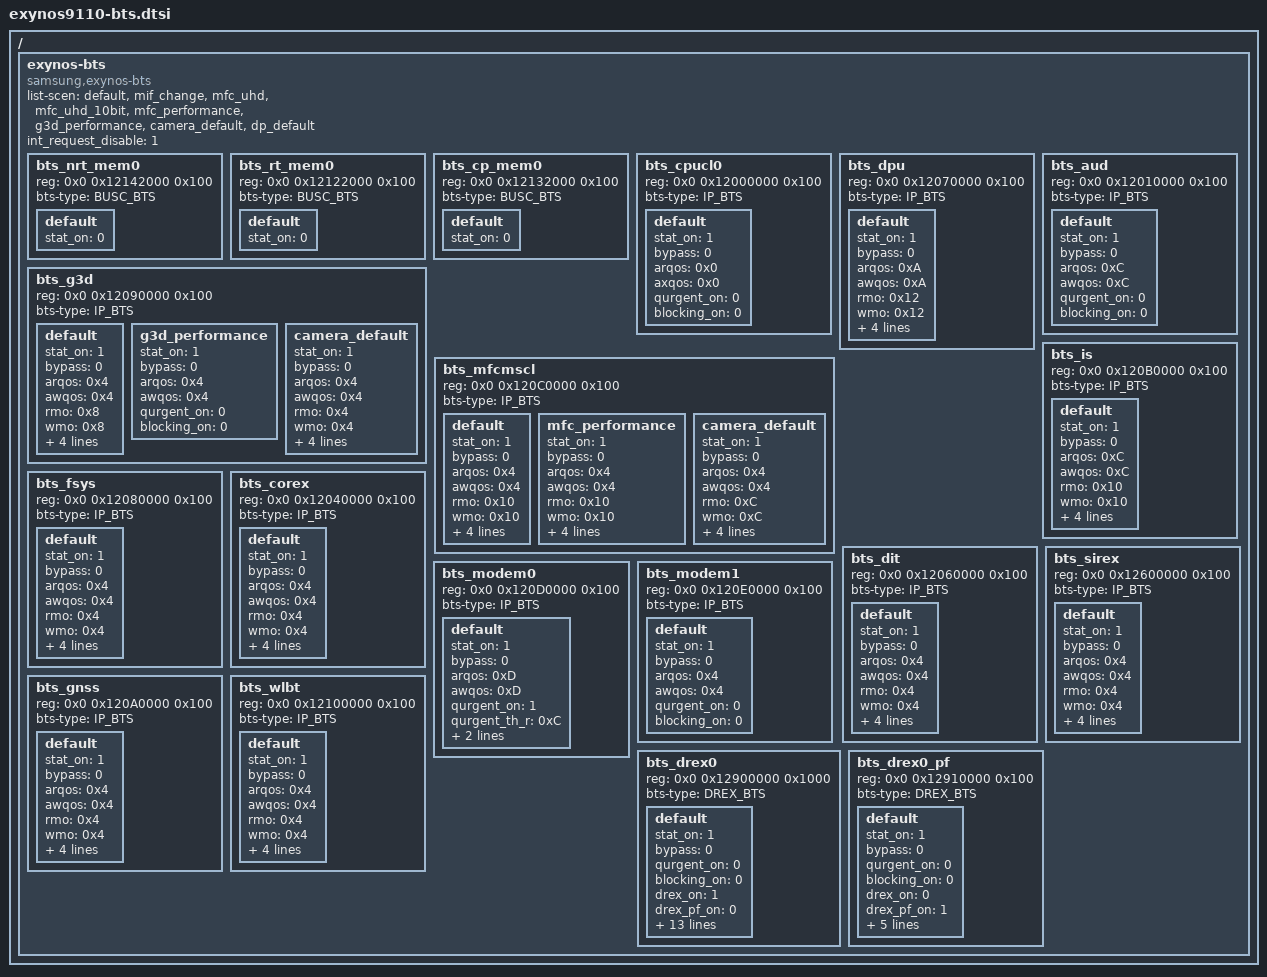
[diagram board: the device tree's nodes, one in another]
/*
 * SAMSUNG EXYNOS SoC BTS device tree source
 *
 * Copyright (c) 2018 Samsung Electronics Co., Ltd.
 *		http://www.samsung.com
 *
 * SAMSUNG EXYNOS SoC BTS device nodes are listed in this file.
 * EXYNOS based board files should include this file.
 *
 * This program is free software; you can redistribute it and/or modify
 * it under the terms of the GNU General Public License version 2 as
 * published by the Free Software Foundation.
 *
 */

#include <dt-bindings/soc/samsung/exynos-bts.h>

/ {
	exynos-bts {
		compatible = "samsung,exynos-bts";
		#address-cells = <2>;
		#size-cells = <1>;
		ranges;

		list-scen = "default",
			    "mif_change",
			    "mfc_uhd",
			    "mfc_uhd_10bit",
			    "mfc_performance",
			    "g3d_performance",
			    "camera_default",
			    "dp_default";

		int_request_disable = <1>;

		bts_nrt_mem0 {
			reg = <0x0 0x12142000 0x100>;
			status = "okay";
			bts-type = <BUSC_BTS>;
			default {
				stat_on = <0>;
			};
		};
		bts_rt_mem0 {
			reg = <0x0 0x12122000 0x100>;
			status = "okay";
			bts-type = <BUSC_BTS>;
			default {
				stat_on = <0>;
			};
		};
		bts_cp_mem0 {
			reg = <0x0 0x12132000 0x100>;
			status = "okay";
			bts-type = <BUSC_BTS>;
			default {
				stat_on = <0>;
			};
		};
		bts_cpucl0 {
			reg = <0x0 0x12000000 0x100>;
			status = "okay";
			bts-type = <IP_BTS>;
			default {
				stat_on = <1>;
				bypass = <0>;
				arqos = <0x0>;
				axqos = <0x0>;
				qurgent_on = <0>;
				blocking_on = <0>;
			};
		};
		bts_dpu {
			reg = <0x0 0x12070000 0x100>;
			status = "okay";
			bts-type = <IP_BTS>;
			default {
				stat_on = <1>;
				bypass = <0>;
				arqos = <0xA>;
				awqos = <0xA>;
				rmo = <0x12>;
				wmo = <0x12>;
				qurgent_on = <1>;
				qurgent_th_r = <0x20>;
				qurgent_th_w = <0x20>;
				blocking_on = <0>;
			};
		};
		bts_aud {
			reg = <0x0 0x12010000 0x100>;
			status = "okay";
			bts-type = <IP_BTS>;
			default {
				stat_on = <1>;
				bypass = <0>;
				arqos = <0xC>;
				awqos = <0xC>;
				qurgent_on = <0>;
				blocking_on = <0>;
			};
		};
		bts_g3d {
			reg = <0x0 0x12090000 0x100>;
			status = "okay";
			bts-type = <IP_BTS>;
			default {
				stat_on = <1>;
				bypass = <0>;
				arqos = <0x4>;
				awqos = <0x4>;
				rmo = <0x8>;
				wmo = <0x8>;
				qurgent_on = <0>;
				blocking_on = <1>;
				qmax0_limit_r = <0x1>;
				qmax0_limit_w = <0x1>;
			};
			g3d_performance {
				stat_on = <1>;
				bypass = <0>;
				arqos = <0x4>;
				awqos = <0x4>;
				qurgent_on = <0>;
				blocking_on = <0>;
			};
			camera_default {
				stat_on = <1>;
				bypass = <0>;
				arqos = <0x4>;
				awqos = <0x4>;
				rmo = <0x4>;
				wmo = <0x4>;
				qurgent_on = <0>;
				blocking_on = <1>;
				qmax0_limit_r = <0x1>;
				qmax0_limit_w = <0x1>;
			};

		};
		bts_mfcmscl {
			reg = <0x0 0x120C0000 0x100>;
			status = "okay";
			bts-type = <IP_BTS>;
			default {
				stat_on = <1>;
				bypass = <0>;
				arqos = <0x4>;
				awqos = <0x4>;
				rmo = <0x10>;
				wmo = <0x10>;
				qurgent_on = <0>;
				blocking_on = <1>;
				qmax0_limit_r = <0x1>;
				qmax0_limit_w = <0x1>;
			};
			mfc_performance {
				stat_on = <1>;
				bypass = <0>;
				arqos = <0x4>;
				awqos = <0x4>;
				rmo = <0x10>;
				wmo = <0x10>;
				qurgent_on = <0>;
				blocking_on = <1>;
				qmax0_limit_r = <0x1>;
				qmax0_limit_w = <0x1>;
			};
			camera_default {
				stat_on = <1>;
				bypass = <0>;
				arqos = <0x4>;
				awqos = <0x4>;
				rmo = <0xC>;
				wmo = <0xC>;
				qurgent_on = <0>;
				blocking_on = <1>;
				qmax0_limit_r = <0x1>;
				qmax0_limit_w = <0x1>;
			};
		};
		bts_is {
			reg = <0x0 0x120B0000 0x100>;
			status = "okay";
			bts-type = <IP_BTS>;
			default {
				stat_on = <1>;
				bypass = <0>;
				arqos = <0xC>;
				awqos = <0xC>;
				rmo = <0x10>;
				wmo = <0x10>;
				qurgent_on = <1>;
				qurgent_th_r = <0x10>;
				qurgent_th_w = <0x10>;
				blocking_on = <0>;
			};
		};
		bts_fsys {
			reg = <0x0 0x12080000 0x100>;
			status = "okay";
			bts-type = <IP_BTS>;
			default {
				stat_on = <1>;
				bypass = <0>;
				arqos = <0x4>;
				awqos = <0x4>;
				rmo = <0x4>;
				wmo = <0x4>;
				qurgent_on = <0>;
				blocking_on = <1>;
				qmax0_limit_r = <0x1>;
				qmax0_limit_w = <0x1>;
			};
		};
		bts_corex {
			reg = <0x0 0x12040000 0x100>;
			status = "okay";
			bts-type = <IP_BTS>;
			default {
				stat_on = <1>;
				bypass = <0>;
				arqos = <0x4>;
				awqos = <0x4>;
				rmo = <0x4>;
				wmo = <0x4>;
				qurgent_on = <0>;
				blocking_on = <1>;
				qmax0_limit_r = <0x1>;
				qmax0_limit_w = <0x1>;
			};
		};
		bts_dit {
			reg = <0x0 0x12060000 0x100>;
			status = "okay";
			bts-type = <IP_BTS>;
			default {
				stat_on = <1>;
				bypass = <0>;
				arqos = <0x4>;
				awqos = <0x4>;
				rmo = <0x4>;
				wmo = <0x4>;
				qurgent_on = <0>;
				blocking_on = <1>;
				qmax0_limit_r = <0x1>;
				qmax0_limit_w = <0x1>;
			};
		};
		bts_sirex {
			reg = <0x0 0x12600000 0x100>;
			status = "okay";
			bts-type = <IP_BTS>;
			default {
				stat_on = <1>;
				bypass = <0>;
				arqos = <0x4>;
				awqos = <0x4>;
				rmo = <0x4>;
				wmo = <0x4>;
				qurgent_on = <0>;
				blocking_on = <1>;
				qmax0_limit_r = <0x1>;
				qmax0_limit_w = <0x1>;
			};
		};
		bts_modem0 {
			reg = <0x0 0x120D0000 0x100>;
			status = "okay";
			bts-type = <IP_BTS>;
			default {
				stat_on = <1>;
				bypass = <0>;
				arqos = <0xD>;
				awqos = <0xD>;
				qurgent_on = <1>;
				qurgent_th_r = <0xC>;
				qurgent_th_w = <0xC>;
				blocking_on = <0>;
			};
		};
		bts_modem1 {
			reg = <0x0 0x120E0000 0x100>;
			status = "okay";
			bts-type = <IP_BTS>;
			default {
				stat_on = <1>;
				bypass = <0>;
				arqos = <0x4>;
				awqos = <0x4>;
				qurgent_on = <0>;
				blocking_on = <0>;
			};
		};
		bts_gnss {
			reg = <0x0 0x120A0000 0x100>;
			status = "okay";
			bts-type = <IP_BTS>;
			default {
				stat_on = <1>;
				bypass = <0>;
				arqos = <0x4>;
				awqos = <0x4>;
				rmo = <0x4>;
				wmo = <0x4>;
				qurgent_on = <0>;
				blocking_on = <1>;
				qmax0_limit_r = <0x1>;
				qmax0_limit_w = <0x1>;
			};
		};
		bts_wlbt {
			reg = <0x0 0x12100000 0x100>;
			status = "okay";
			bts-type = <IP_BTS>;
			default {
				stat_on = <1>;
				bypass = <0>;
				arqos = <0x4>;
				awqos = <0x4>;
				rmo = <0x4>;
				wmo = <0x4>;
				qurgent_on = <0>;
				blocking_on = <1>;
				qmax0_limit_r = <0x1>;
				qmax0_limit_w = <0x1>;
			};
		};

		bts_drex0 {
			reg = <0x0 0x12900000 0x1000>;
			status = "okay";
			bts-type = <DREX_BTS>;
			default {
				stat_on = <1>;
				bypass = <0>;
				qurgent_on = <0>;
				blocking_on = <0>;
				drex_on = <1>;
				drex_pf_on = <0>;
				write_flush_config_0 = <0x50100C02>;
				write_flush_config_1 = <0x1008100A>;
				drex_timeout = <0x000A0180>,
					     <0x000A0100>,
					     <0x000A0100>,
					     <0x000A0100>,
					     <0x000A0100>,
					     <0x000A0100>,
					     <0x000A0100>,
					     <0x000A0100>,
					     <0x000A0080>,
					     <0x000A0060>,
					     <0x000A0040>,
					     <0x000A0020>,
					     <0x000A0010>,
					     <0x000A0008>,
					     <0x000A0004>,
					     <0x000A0001>;
				vc_timer_th = <0x00C100C1>,
					    <0x00C100C1>,
					    <0x00C100C1>,
					    <0x00C100C1>,
					    <0x00C100C1>,
					    <0x000D001A>,
					    <0x00030007>,
					    <0x00010001>;
				cutoff_con = <0x00000005>;
				brb_cutoff_con = <0x00020002>;
			};
		};
		bts_drex0_pf {
			reg = <0x0 0x12910000 0x100>;
			status = "okay";
			bts-type = <DREX_BTS>;
			default {
				stat_on = <1>;
				bypass = <0>;
				qurgent_on = <0>;
				blocking_on = <0>;
				drex_on = <0>;
				drex_pf_on = <1>;
				pf_rreq_thrt_con = <0x00008000>;
				allow_mo_for_region = <0x00000000>;
				pf_qos_timer = <0x00070007>,
					     <0x00070007>,
					     <0x00070007>,
					     <0x00070007>,
					     <0x00070007>,
					     <0x00070007>,
					     <0x00070007>,
					     <0x00070007>;
			};
		};
	};
};
